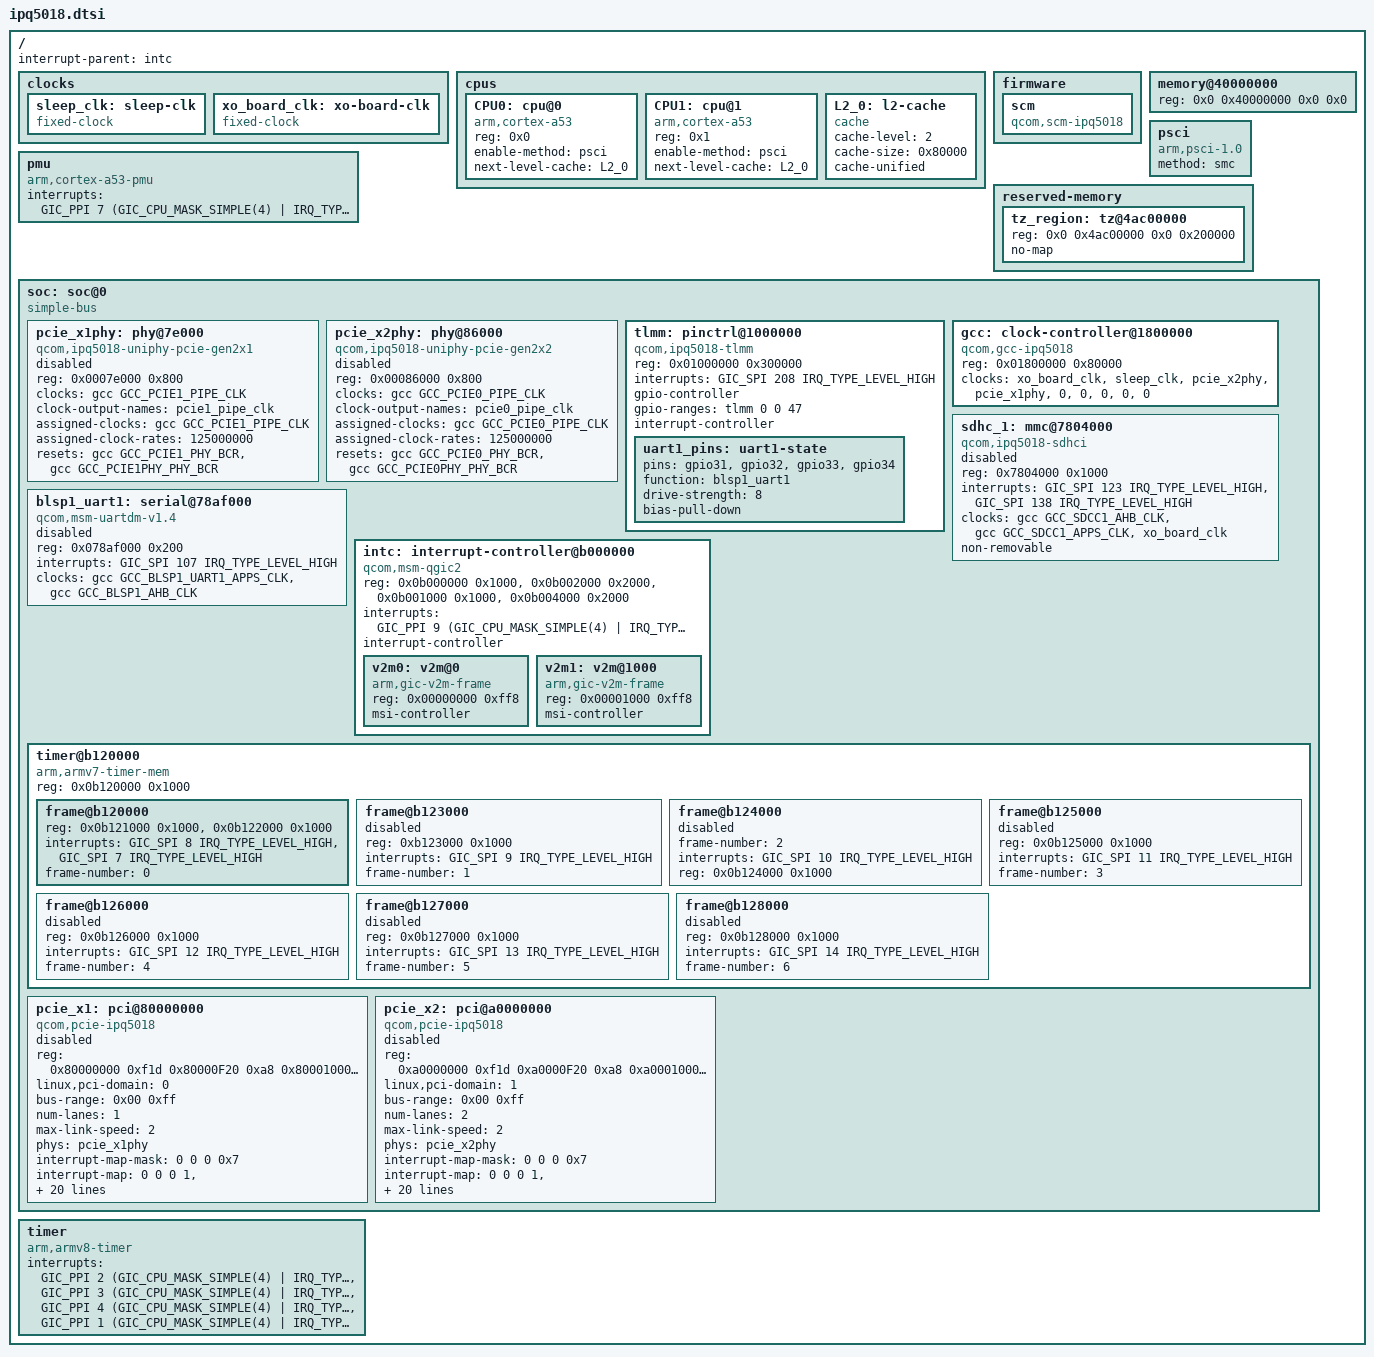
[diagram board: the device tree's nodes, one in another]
// SPDX-License-Identifier: GPL-2.0+ OR BSD-3-Clause
/*
 * IPQ5018 SoC device tree source
 *
 * Copyright (c) 2023 The Linux Foundation. All rights reserved.
 */

#include <dt-bindings/interrupt-controller/arm-gic.h>
#include <dt-bindings/clock/qcom,gcc-ipq5018.h>
#include <dt-bindings/reset/qcom,gcc-ipq5018.h>
#include <dt-bindings/gpio/gpio.h>

/ {
	interrupt-parent = <&intc>;
	#address-cells = <2>;
	#size-cells = <2>;

	clocks {
		sleep_clk: sleep-clk {
			compatible = "fixed-clock";
			#clock-cells = <0>;
		};

		xo_board_clk: xo-board-clk {
			compatible = "fixed-clock";
			#clock-cells = <0>;
		};
	};

	cpus {
		#address-cells = <1>;
		#size-cells = <0>;

		CPU0: cpu@0 {
			device_type = "cpu";
			compatible = "arm,cortex-a53";
			reg = <0x0>;
			enable-method = "psci";
			next-level-cache = <&L2_0>;
		};

		CPU1: cpu@1 {
			device_type = "cpu";
			compatible = "arm,cortex-a53";
			reg = <0x1>;
			enable-method = "psci";
			next-level-cache = <&L2_0>;
		};

		L2_0: l2-cache {
			compatible = "cache";
			cache-level = <2>;
			cache-size = <0x80000>;
			cache-unified;
		};
	};

	firmware {
		scm {
			compatible = "qcom,scm-ipq5018", "qcom,scm";
		};
	};

	memory@40000000 {
		device_type = "memory";
		/* We expect the bootloader to fill in the size */
		reg = <0x0 0x40000000 0x0 0x0>;
	};

	pmu {
		compatible = "arm,cortex-a53-pmu";
		interrupts = <GIC_PPI 7 (GIC_CPU_MASK_SIMPLE(4) | IRQ_TYPE_LEVEL_HIGH)>;
	};

	psci {
		compatible = "arm,psci-1.0";
		method = "smc";
	};

	reserved-memory {
		#address-cells = <2>;
		#size-cells = <2>;
		ranges;

		tz_region: tz@4ac00000 {
			reg = <0x0 0x4ac00000 0x0 0x200000>;
			no-map;
		};
	};

	soc: soc@0 {
		compatible = "simple-bus";
		#address-cells = <1>;
		#size-cells = <1>;
		ranges = <0 0 0 0xffffffff>;

		pcie_x1phy: phy@7e000{
			compatible = "qcom,ipq5018-uniphy-pcie-gen2x1";
			reg = <0x0007e000 0x800>;
			#phy-cells = <0>;
			#clock-cells = <0>;
			clocks = <&gcc GCC_PCIE1_PIPE_CLK>;
			clock-names = "pipe_clk";
			clock-output-names = "pcie1_pipe_clk";
			assigned-clocks = <&gcc GCC_PCIE1_PIPE_CLK>;
			assigned-clock-rates = <125000000>;
			resets = <&gcc GCC_PCIE1_PHY_BCR>,
				 <&gcc GCC_PCIE1PHY_PHY_BCR>;
			reset-names = "phy", "phy_phy";
			status = "disabled";
		};

		pcie_x2phy: phy@86000{
			compatible = "qcom,ipq5018-uniphy-pcie-gen2x2";
			reg = <0x00086000 0x800>;
			#phy-cells = <0>;
			#clock-cells = <0>;
			clocks = <&gcc GCC_PCIE0_PIPE_CLK>;
			clock-names = "pipe_clk";
			clock-output-names = "pcie0_pipe_clk";
			assigned-clocks = <&gcc GCC_PCIE0_PIPE_CLK>;
			assigned-clock-rates = <125000000>;
			resets = <&gcc GCC_PCIE0_PHY_BCR>,
				 <&gcc GCC_PCIE0PHY_PHY_BCR>;
			reset-names = "phy", "phy_phy";
			status = "disabled";
		};

		tlmm: pinctrl@1000000 {
			compatible = "qcom,ipq5018-tlmm";
			reg = <0x01000000 0x300000>;
			interrupts = <GIC_SPI 208 IRQ_TYPE_LEVEL_HIGH>;
			gpio-controller;
			#gpio-cells = <2>;
			gpio-ranges = <&tlmm 0 0 47>;
			interrupt-controller;
			#interrupt-cells = <2>;

			uart1_pins: uart1-state {
				pins = "gpio31", "gpio32", "gpio33", "gpio34";
				function = "blsp1_uart1";
				drive-strength = <8>;
				bias-pull-down;
			};
		};

		gcc: clock-controller@1800000 {
			compatible = "qcom,gcc-ipq5018";
			reg = <0x01800000 0x80000>;
			clocks = <&xo_board_clk>,
				 <&sleep_clk>,
				 <&pcie_x2phy>,
				 <&pcie_x1phy>,
				 <0>,
				 <0>,
				 <0>,
				 <0>,
				 <0>;
			#clock-cells = <1>;
			#reset-cells = <1>;
			#power-domain-cells = <1>;
		};

		sdhc_1: mmc@7804000 {
			compatible = "qcom,ipq5018-sdhci", "qcom,sdhci-msm-v5";
			reg = <0x7804000 0x1000>;
			reg-names = "hc";

			interrupts = <GIC_SPI 123 IRQ_TYPE_LEVEL_HIGH>,
				     <GIC_SPI 138 IRQ_TYPE_LEVEL_HIGH>;
			interrupt-names = "hc_irq", "pwr_irq";

			clocks = <&gcc GCC_SDCC1_AHB_CLK>,
				 <&gcc GCC_SDCC1_APPS_CLK>,
				 <&xo_board_clk>;
			clock-names = "iface", "core", "xo";
			non-removable;
			status = "disabled";
		};

		blsp1_uart1: serial@78af000 {
			compatible = "qcom,msm-uartdm-v1.4", "qcom,msm-uartdm";
			reg = <0x078af000 0x200>;
			interrupts = <GIC_SPI 107 IRQ_TYPE_LEVEL_HIGH>;
			clocks = <&gcc GCC_BLSP1_UART1_APPS_CLK>,
				 <&gcc GCC_BLSP1_AHB_CLK>;
			clock-names = "core", "iface";
			status = "disabled";
		};

		intc: interrupt-controller@b000000 {
			compatible = "qcom,msm-qgic2";
			reg = <0x0b000000 0x1000>,  /* GICD */
			      <0x0b002000 0x2000>,  /* GICC */
			      <0x0b001000 0x1000>,  /* GICH */
			      <0x0b004000 0x2000>;  /* GICV */
			interrupts = <GIC_PPI 9 (GIC_CPU_MASK_SIMPLE(4) | IRQ_TYPE_LEVEL_HIGH)>;
			interrupt-controller;
			#interrupt-cells = <3>;
			#address-cells = <1>;
			#size-cells = <1>;
			ranges = <0 0x0b00a000 0x1ffa>;

			v2m0: v2m@0 {
				compatible = "arm,gic-v2m-frame";
				reg = <0x00000000 0xff8>;
				msi-controller;
			};

			v2m1: v2m@1000 {
				compatible = "arm,gic-v2m-frame";
				reg = <0x00001000 0xff8>;
				msi-controller;
			};
		};

		timer@b120000 {
			compatible = "arm,armv7-timer-mem";
			reg = <0x0b120000 0x1000>;
			#address-cells = <1>;
			#size-cells = <1>;
			ranges;

			frame@b120000 {
				reg = <0x0b121000 0x1000>,
				      <0x0b122000 0x1000>;
				interrupts = <GIC_SPI 8 IRQ_TYPE_LEVEL_HIGH>,
					     <GIC_SPI 7 IRQ_TYPE_LEVEL_HIGH>;
				frame-number = <0>;
			};

			frame@b123000 {
				reg = <0xb123000 0x1000>;
				interrupts = <GIC_SPI 9 IRQ_TYPE_LEVEL_HIGH>;
				frame-number = <1>;
				status = "disabled";
			};

			frame@b124000 {
				frame-number = <2>;
				interrupts = <GIC_SPI 10 IRQ_TYPE_LEVEL_HIGH>;
				reg = <0x0b124000 0x1000>;
				status = "disabled";
			};

			frame@b125000 {
				reg = <0x0b125000 0x1000>;
				interrupts = <GIC_SPI 11 IRQ_TYPE_LEVEL_HIGH>;
				frame-number = <3>;
				status = "disabled";
			};

			frame@b126000 {
				reg = <0x0b126000 0x1000>;
				interrupts = <GIC_SPI 12 IRQ_TYPE_LEVEL_HIGH>;
				frame-number = <4>;
				status = "disabled";
			};

			frame@b127000 {
				reg = <0x0b127000 0x1000>;
				interrupts = <GIC_SPI 13 IRQ_TYPE_LEVEL_HIGH>;
				frame-number = <5>;
				status = "disabled";
			};

			frame@b128000 {
				reg = <0x0b128000 0x1000>;
				interrupts = <GIC_SPI 14 IRQ_TYPE_LEVEL_HIGH>;
				frame-number = <6>;
				status = "disabled";
			};
		};

		pcie_x1: pci@80000000 {
			compatible = "qcom,pcie-ipq5018";
			reg =  <0x80000000 0xf1d
				0x80000F20 0xa8
				0x80001000 0x1000
				0x78000 0x3000
				0x80100000 0x1000>;
			reg-names = "dbi", "elbi", "atu", "parf", "config";
			device_type = "pci";
			linux,pci-domain = <0>;
			bus-range = <0x00 0xff>;
			num-lanes = <1>;
			max-link-speed = <2>;
			#address-cells = <3>;
			#size-cells = <2>;

			phys = <&pcie_x1phy>;
			phy-names ="pciephy";

			ranges = <0x81000000 0 0x80200000 0x80200000
				  0 0x00100000   /* downstream I/O */
				  0x82000000 0 0x80300000 0x80300000
				  0 0x10000000>; /* non-prefetchable memory */

			#interrupt-cells = <1>;
			interrupt-map-mask = <0 0 0 0x7>;
			interrupt-map = <0 0 0 1 &intc 0 142
					 IRQ_TYPE_LEVEL_HIGH>, /* int_a */
					<0 0 0 2 &intc 0 143
					 IRQ_TYPE_LEVEL_HIGH>, /* int_b */
					<0 0 0 3 &intc 0 144
					 IRQ_TYPE_LEVEL_HIGH>, /* int_c */
					<0 0 0 4 &intc 0 145
					 IRQ_TYPE_LEVEL_HIGH>; /* int_d */

			interrupts = <GIC_SPI 119 IRQ_TYPE_LEVEL_HIGH>;
			interrupt-names = "global_irq";

			clocks = <&gcc GCC_SYS_NOC_PCIE1_AXI_CLK>,
				 <&gcc GCC_PCIE1_AXI_M_CLK>,
				 <&gcc GCC_PCIE1_AXI_S_CLK>,
				 <&gcc GCC_PCIE1_AHB_CLK>,
				 <&gcc GCC_PCIE1_AUX_CLK>,
				 <&gcc GCC_PCIE1_AXI_S_BRIDGE_CLK>;

			clock-names = "iface",
				      "axi_m",
				      "axi_s",
				      "ahb",
				      "aux",
				      "axi_bridge";

			resets = <&gcc GCC_PCIE1_PIPE_ARES>,
				 <&gcc GCC_PCIE1_SLEEP_ARES>,
				 <&gcc GCC_PCIE1_CORE_STICKY_ARES>,
				 <&gcc GCC_PCIE1_AXI_MASTER_ARES>,
				 <&gcc GCC_PCIE1_AXI_SLAVE_ARES>,
				 <&gcc GCC_PCIE1_AHB_ARES>,
				 <&gcc GCC_PCIE1_AXI_MASTER_STICKY_ARES>,
				 <&gcc GCC_PCIE1_AXI_SLAVE_STICKY_ARES>;

			reset-names = "pipe",
				      "sleep",
				      "sticky",
				      "axi_m",
				      "axi_s",
				      "ahb",
				      "axi_m_sticky",
				      "axi_s_sticky";

			msi-map = <0x0 &v2m0 0x0 0xff8>;
			status = "disabled";
		};

		pcie_x2: pci@a0000000 {
			compatible = "qcom,pcie-ipq5018";
			reg =  <0xa0000000 0xf1d
				0xa0000F20 0xa8
				0xa0001000 0x1000
				0x80000 0x3000
				0xa0100000 0x1000>;
			reg-names = "dbi", "elbi", "atu", "parf", "config";
			device_type = "pci";
			linux,pci-domain = <1>;
			bus-range = <0x00 0xff>;
			num-lanes = <2>;
			max-link-speed = <2>;
			#address-cells = <3>;
			#size-cells = <2>;

			phys = <&pcie_x2phy>;
			phy-names ="pciephy";

			ranges = <0x81000000 0 0xa0200000 0xa0200000
				  0 0x00100000   /* downstream I/O */
				  0x82000000 0 0xa0300000 0xa0300000
				  0 0x10000000>; /* non-prefetchable memory */

			#interrupt-cells = <1>;
			interrupt-map-mask = <0 0 0 0x7>;
			interrupt-map = <0 0 0 1 &intc 0 75
					 IRQ_TYPE_LEVEL_HIGH>, /* int_a */
					<0 0 0 2 &intc 0 78
					 IRQ_TYPE_LEVEL_HIGH>, /* int_b */
					<0 0 0 3 &intc 0 79
					 IRQ_TYPE_LEVEL_HIGH>, /* int_c */
					<0 0 0 4 &intc 0 83
					 IRQ_TYPE_LEVEL_HIGH>; /* int_d */

			interrupts = <GIC_SPI 51 IRQ_TYPE_LEVEL_HIGH>;
			interrupt-names = "global_irq";

			clocks = <&gcc GCC_SYS_NOC_PCIE0_AXI_CLK>,
				 <&gcc GCC_PCIE0_AXI_M_CLK>,
				 <&gcc GCC_PCIE0_AXI_S_CLK>,
				 <&gcc GCC_PCIE0_AHB_CLK>,
				 <&gcc GCC_PCIE0_AUX_CLK>,
				 <&gcc GCC_PCIE0_AXI_S_BRIDGE_CLK>;

			clock-names = "iface",
				      "axi_m",
				      "axi_s",
				      "ahb",
				      "aux",
				      "axi_bridge";

			resets = <&gcc GCC_PCIE0_PIPE_ARES>,
				 <&gcc GCC_PCIE0_SLEEP_ARES>,
				 <&gcc GCC_PCIE0_CORE_STICKY_ARES>,
				 <&gcc GCC_PCIE0_AXI_MASTER_ARES>,
				 <&gcc GCC_PCIE0_AXI_SLAVE_ARES>,
				 <&gcc GCC_PCIE0_AHB_ARES>,
				 <&gcc GCC_PCIE0_AXI_MASTER_STICKY_ARES>,
				 <&gcc GCC_PCIE0_AXI_SLAVE_STICKY_ARES>;

			reset-names = "pipe",
				      "sleep",
				      "sticky",
				      "axi_m",
				      "axi_s",
				      "ahb",
				      "axi_m_sticky",
				      "axi_s_sticky";

			msi-map = <0x0 &v2m0 0x0 0xff8>;
			status = "disabled";
		};

	};

	timer {
		compatible = "arm,armv8-timer";
		interrupts = <GIC_PPI 2 (GIC_CPU_MASK_SIMPLE(4) | IRQ_TYPE_LEVEL_LOW)>,
			     <GIC_PPI 3 (GIC_CPU_MASK_SIMPLE(4) | IRQ_TYPE_LEVEL_LOW)>,
			     <GIC_PPI 4 (GIC_CPU_MASK_SIMPLE(4) | IRQ_TYPE_LEVEL_LOW)>,
			     <GIC_PPI 1 (GIC_CPU_MASK_SIMPLE(4) | IRQ_TYPE_LEVEL_LOW)>;
	};
};
